# AVR32DU14 device description
Architecture: AVR8X; Family: AVR
Registers are 8-bit, read-write, reset 0x0 unless marked. A register's access mark holds for its fields unless they carry their own. Offsets are from the block's base; [hi:lo] are bit positions; {n}, {i} and the like mark numbered series; 'fields as' and 'values as' point back to an identical list.

## CRCSCAN
Instances: CRCSCAN 0x0120
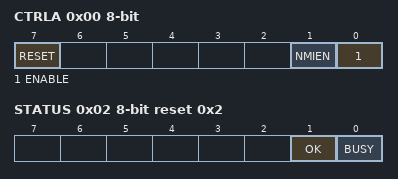
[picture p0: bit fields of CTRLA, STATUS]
0x00 CTRLA — Control A
  [7] RESET — Reset CRC scan
  [1] NMIEN — Enable NMI Trigger
  [0] ENABLE — Enable CRC scan
0x01 CTRLB — Control B
  [1:0] SRC — CRC Source
    0=FLASH (CRC on entire flash); 1=BOOTAPP (CRC on boot and appl section of flash); 2=BOOT (CRC on boot section of flash)
0x02 STATUS ro reset 0x2
  [1] OK — CRC Ok
  [0] BUSY — CRC Busy

## EVSYS — Event System
Instances: EVSYS 0x0200
0x00 SWEVENTA — Software Event A
  [7:0] SWEVENTA wo — Software event on channel select
    1=CH0 (Software event on channel 0); 2=CH1 (Software event on channel 1); 4=CH2 (Software event on channel 2); 8=CH3 (Software event on channel 3); 16=CH4 (Software event on channel 4); 32=CH5 (Software event on channel 5); 64=CH6 (Software event on channel 6); 128=CH7 (Software event on channel 7)
{0x10+i} CHANNEL{i} (i=0..5) — Multiplexer Channel {i}
  [7:0] CHANNEL — Channel generator select
    0=OFF; 1=UPDI_SYNCH (UPDI SYNCH Character); 6=RTC_OVF (Real Time Counter Overflow); 7=RTC_CMP (Real Time Counter Compare); 8=RTC_EVGEN0 (Real Time Counter Event Output 0); 9=RTC_EVGEN1 (Real Time Counter Event Output 1); {v}=CCL_LUT{v-16} (Configurable Custom Logic LUT{v-16}) (v=16..19); 32=AC0_OUT (Analog Comparator 0 Out); 36=ADC0_RESRDY (ADC0 Result Ready); 37=ADC0_SAMPRDY (ADC0 Sample Ready); 38=ADC0_WCMP (ADC0 Window Comparator); 64=PORTA_EVGEN0 (Port A Event 0); 65=PORTA_EVGEN1 (Port A Event 1); 68=PORTC_EVGEN0 (Port C Event 0); 69=PORTC_EVGEN1 (Port C Event 1); 70=PORTD_EVGEN0 (Port D Event 0); 71=PORTD_EVGEN1 (Port D Event 1); 74=PORTF_EVGEN0 (Port F Event 0); 75=PORTF_EVGEN1 (Port F Event 1); 96=USART0_XCK; 97=USART1_XCK; 104=SPI0_SCK; 128=TCA0_OVF_LUNF (Timer/Counter A0 Overflow / Low Byte Timer Underflow); 129=TCA0_HUNF (Timer/Counter A0 High Byte Timer Underflow); 132=TCA0_CMP0_LCMP0 (Timer/Counter A0 Compare 0 / Low Byte Compare 0); 133=TCA0_CMP1_LCMP1 (Timer/Counter A0 Compare 1 / Low Byte Compare 1); 134=TCA0_CMP2_LCMP2 (Timer/Counter A0 Compare 2 / Low Byte Compare 2); 160=TCB0_CAPT (Timer/Counter B0 Capture); 161=TCB0_OVF (Timer/Counter B0 Overflow); 162=TCB1_CAPT (Timer/Counter B1 Capture); 163=TCB1_OVF (Timer/Counter B1 Overflow); 192=USB0_SETUP (USB0 Setup Received); 193=USB0_SOF (USB0 SOF Received); 194=USB0_CRC (USB0 CRC Error); 195=USB0_UNFOVF (USB0 Underflow / Overflow); 196=USB0_RX (USB0 Data Byte Received); 197=USB0_TX (USB0 Data Byte Transmitted)
{0x20+2i} USERCCLLUT{i}A (i=0..3) — CCL{i} Event A
  [7:0] USER — User channel select
    0=OFF; {v}=CHANNEL{v-1} (Connect user to event channel {v-1}) (v=1..6)
{0x21+2i} USERCCLLUT{i}B (i=0..3) — CCL{i} Event B
  fields as USERCCLLUT0A
0x28 USERADC0START — ADC0
  fields as USERCCLLUT0A
0x29 USEREVSYSEVOUTA — EVOUTA
  fields as USERCCLLUT0A
0x2A USEREVSYSEVOUTD — EVOUTD
  fields as USERCCLLUT0A
0x2B USEREVSYSEVOUTF — EVOUTF
  fields as USERCCLLUT0A
0x2C USERUSART0IRDA — USART0
  fields as USERCCLLUT0A
0x2D USERUSART1IRDA — USART1
  fields as USERCCLLUT0A
0x2E USERTCA0CNTA — TCA0 Event A
  fields as USERCCLLUT0A
0x2F USERTCA0CNTB — TCA0 Event B
  fields as USERCCLLUT0A
0x30 USERTCB0CAPT — TCB0 Event A
  fields as USERCCLLUT0A
0x31 USERTCB0COUNT — TCB0 Event B
  fields as USERCCLLUT0A
0x32 USERTCB1CAPT — TCB1 Event A
  fields as USERCCLLUT0A
0x33 USERTCB1COUNT — TCB1 Event B
  fields as USERCCLLUT0A

## FUSE — Fuses
Instances: FUSE 0x1050
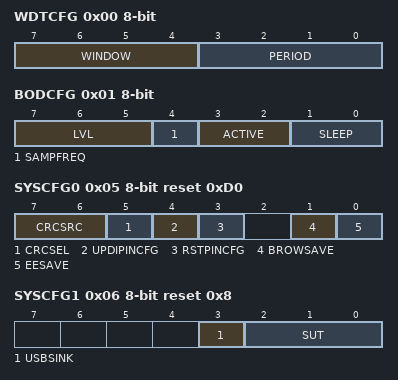
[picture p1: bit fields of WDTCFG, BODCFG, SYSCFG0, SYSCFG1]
0x00 WDTCFG — Watchdog Configuration
  [7:4] WINDOW — Watchdog Window Timeout Period
    0=OFF (Window mode off); 1=8CLK (8 cycles (8ms)); 2=16CLK (16 cycles (16ms)); 3=32CLK (32 cycles (32ms)); 4=64CLK (64 cycles (64ms)); 5=128CLK (128 cycles (0.128s)); 6=256CLK (256 cycles (0.256s)); 7=512CLK (512 cycles (0.512s)); 8=1KCLK (1K cycles (1.0s)); 9=2KCLK (2K cycles (2.0s)); 10=4KCLK (4K cycles (4.0s)); 11=8KCLK (8K cycles (8.0s))
  [3:0] PERIOD — Watchdog Timeout Period
    0=OFF (Watch-Dog timer Off); 1=8CLK (8 cycles (8ms)); 2=16CLK (16 cycles (16ms)); 3=32CLK (32 cycles (32ms)); 4=64CLK (64 cycles (64ms)); 5=128CLK (128 cycles (0.128s)); 6=256CLK (256 cycles (0.256s)); 7=512CLK (512 cycles (0.512s)); 8=1KCLK (1K cycles (1.0s)); 9=2KCLK (2K cycles (2.0s)); 10=4KCLK (4K cycles (4.0s)); 11=8KCLK (8K cycles (8.0s))
0x01 BODCFG — BOD Configuration
  [7:5] LVL — BOD Level
    0=BODLEVEL0 (1.9V); 1=BODLEVEL1 (2.45V); 2=BODLEVEL2 (2.7V); 3=BODLEVEL3 (2.85V)
  [4] SAMPFREQ — BOD Sample Frequency
    0=128Hz (Sample frequency is 128 Hz); 1=32Hz (Sample frequency is 32 Hz)
  [3:2] ACTIVE — BOD Operation in Active Mode
    0=DISABLE (BOD disabled); 1=ENABLE (BOD enabled in continuous mode); 2=SAMPLE (BOD enabled in sampled mode); 3=ENABLEWAIT (BOD enabled in continuous mode. Execution is halted at wake-up until BOD is running.)
  [1:0] SLEEP — BOD Operation in Sleep Mode
    0=DISABLE (BOD disabled); 1=ENABLE (BOD enabled in continuous mode); 2=SAMPLE (BOD enabled in sampled mode)
0x02 OSCCFG — Oscillator Configuration
  [2:0] CLKSEL — Frequency Select
    0=OSCHF (1-32MHz internal oscillator); 1=OSC32K (32.768kHz internal oscillator)
0x05 SYSCFG0 reset 0xD0 — System Configuration 0
  [7:6] CRCSRC — CRC Source
    0=FLASH (CRC of full Flash (boot, application code and application data)); 1=BOOT (CRC of boot section); 2=BOOTAPP (CRC of application code and boot sections); 3=NOCRC
  [5] CRCSEL — CRC Select
    0=CRC16 (Enable CRC16); 1=CRC32 (Enable CRC32)
  [4] UPDIPINCFG — UPDI Pin Configuration
    0=GPIO (GPIO Mode); 1=UPDI (UPDI Mode)
  [3] RSTPINCFG — Reset Pin Configuration
    0=GPIO (GPIO mode); 1=RST (Reset mode)
  [1] BROWSAVE — Boot Row Save
  [0] EESAVE — EEPROM Save
0x06 SYSCFG1 reset 0x8 — System Configuration 1
  [3] USBSINK — USB Voltage Regulator Current Sink Enable
    0=DISABLE (USB VREG can not sink current); 1=ENABLE (USB VREG can sink current)
  [2:0] SUT — Startup Time
    0=0MS; 1=1MS; 2=2MS; 3=4MS; 4=8MS; 5=16MS; 6=32MS; 7=64MS
0x07 CODESIZE — Code Section Size
0x08 BOOTSIZE — Boot Section Size
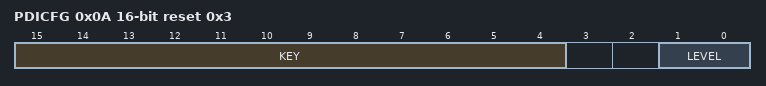
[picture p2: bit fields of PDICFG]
0x0A PDICFG 16-bit reset 0x3 — Programming and Debugging Interface Configuration
  [15:4] KEY — NVM Protection Activation Key
    0=NOTACT (Not Active); 0xB45=NVMACT (NVM Protection Active)
  [1:0] LEVEL — Protection Level
    2=NVMACCDIS (NVM Access through UPDI disabled); 3=BASIC (UPDI and UPDI pins working normally)
